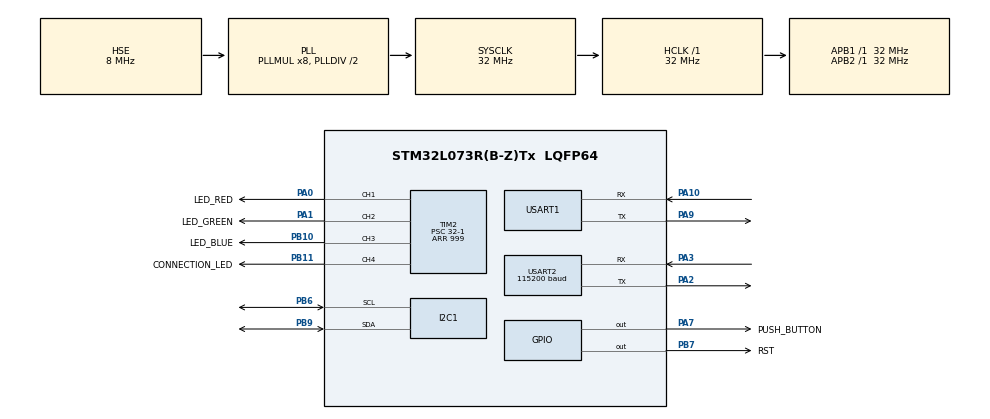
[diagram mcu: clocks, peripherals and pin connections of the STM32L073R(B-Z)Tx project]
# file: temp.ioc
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I2C1.Timing=0x00B07CB4
Mcu.Family=STM32L0
Mcu.Name=STM32L073R(B-Z)Tx
Mcu.Package=LQFP64
NVIC.USART1_IRQn=true\:0\:0\:false\:false\:true\:true\:true\:true
PA0.GPIO_Label=LED_RED
PA0.Signal=S_TIM2_CH1
PA1.GPIO_Label=LED_GREEN
PA1.Signal=S_TIM2_CH2
PA10.Mode=Asynchronous
PA10.Signal=USART1_RX
PA13.Mode=Serial_Wire
PA13.Signal=SYS_SWDIO
PA14.Mode=Serial_Wire
PA14.Signal=SYS_SWCLK
PA2.Mode=Asynchronous
PA2.Signal=USART2_TX
PA3.Mode=Asynchronous
PA3.Signal=USART2_RX
PA7.GPIO_Label=PUSH_BUTTON
PA7.Signal=GPIO_Output
PA9.Mode=Asynchronous
PA9.Signal=USART1_TX
PB10.GPIO_Label=LED_BLUE
PB10.Signal=S_TIM2_CH3
PB11.GPIO_Label=CONNECTION_LED
PB11.Signal=S_TIM2_CH4
PB6.Mode=I2C
PB6.Signal=I2C1_SCL
PB7.GPIO_Label=RST
PB7.Signal=GPIO_Output
PB9.Mode=I2C
PB9.Signal=I2C1_SDA
PH0-OSC_IN.Mode=HSE-External-Clock-Source
PH0-OSC_IN.Signal=RCC_OSC_IN
ProjectManager.HeapSize=0x200
ProjectManager.StackSize=0x400
ProjectManager.TargetToolchain=STM32CubeIDE
RCC.AHBFreq_Value=32000000
RCC.APB1Freq_Value=32000000
RCC.APB1TimFreq_Value=32000000
RCC.APB2Freq_Value=32000000
RCC.APB2TimFreq_Value=32000000
RCC.HCLKFreq_Value=32000000
RCC.HSE_VALUE=8000000
RCC.HSI16_VALUE=16000000
RCC.HSI48_VALUE=48000000
RCC.HSI_VALUE=16000000
RCC.LSE_VALUE=32768
RCC.MSI_VALUE=2097000
RCC.PLLMUL=RCC_PLLMUL_8
RCC.PLLSourceVirtual=RCC_PLLSOURCE_HSE
RCC.SYSCLKFreq_VALUE=32000000
RCC.SYSCLKSource=RCC_SYSCLKSOURCE_PLLCLK
RCC.VCOOutputFreq_Value=64000000
SH.S_TIM2_CH1.0=TIM2_CH1,PWM Generation1 CH1
SH.S_TIM2_CH2.0=TIM2_CH2,PWM Generation2 CH2
SH.S_TIM2_CH3.0=TIM2_CH3,PWM Generation3 CH3
SH.S_TIM2_CH4.0=TIM2_CH4,PWM Generation4 CH4
TIM2.Channel-PWM\ Generation1\ CH1=TIM_CHANNEL_1
TIM2.Channel-PWM\ Generation2\ CH2=TIM_CHANNEL_2
TIM2.Channel-PWM\ Generation3\ CH3=TIM_CHANNEL_3
TIM2.Channel-PWM\ Generation4\ CH4=TIM_CHANNEL_4
TIM2.Period=999
TIM2.Prescaler=32-1
TIM6.Period=65535-1
TIM6.Prescaler=32-1
USART1.VirtualMode-Asynchronous=VM_ASYNC
USART2.BaudRate=115200
USART2.VirtualMode-Asynchronous=VM_ASYNC
VP_TIM6_VS_ClockSourceINT.Mode=Enable_Timer
board=NUCLEO-L073RZ

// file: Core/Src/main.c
/* USER CODE BEGIN Header */
/**
 ******************************************************************************
 * @file           : main.c
 * @brief          : Main program body
 ******************************************************************************
 * @attention
 *
 * Copyright (c) 2026 STMicroelectronics.
 * All rights reserved.
 *
 * This software is licensed under terms that can be found in the LICENSE file
 * in the root directory of this software component.
 * If no LICENSE file comes with this software, it is provided AS-IS.
 *
 ******************************************************************************
 */
/* USER CODE END Header */
#include "main.h"
#include "i2c.h"
#include "tim.h"
#include "usart.h"
#include "gpio.h"

/* USER CODE BEGIN Includes */
#include "app/entry.h"
/* USER CODE END Includes */

void SystemClock_Config(void);

int main(void)
{

  /* MCU Configuration--------------------------------------------------------*/

  /* Reset of all peripherals, Initializes the Flash interface and the Systick. */
  HAL_Init();

  /* Configure the system clock */
  SystemClock_Config();

  /* Initialize all configured peripherals */
  MX_GPIO_Init();
  MX_I2C1_Init();
  MX_TIM2_Init();
  MX_TIM6_Init();
  MX_USART1_UART_Init();
  MX_USART2_UART_Init();
  /* USER CODE BEGIN 2 */

	app_main();

  /* USER CODE END 2 */

  /* Infinite loop */
	while (1)
	{

	}
}

void SystemClock_Config(void)
{
  RCC_OscInitTypeDef RCC_OscInitStruct = {0};
  RCC_ClkInitTypeDef RCC_ClkInitStruct = {0};
  RCC_PeriphCLKInitTypeDef PeriphClkInit = {0};

  /** Configure the main internal regulator output voltage
  */
  __HAL_PWR_VOLTAGESCALING_CONFIG(PWR_REGULATOR_VOLTAGE_SCALE1);

  /** Initializes the RCC Oscillators according to the specified parameters
  * in the RCC_OscInitTypeDef structure.
  */
  RCC_OscInitStruct.OscillatorType = RCC_OSCILLATORTYPE_HSE;
  RCC_OscInitStruct.HSEState = RCC_HSE_BYPASS;
  RCC_OscInitStruct.PLL.PLLState = RCC_PLL_ON;
  RCC_OscInitStruct.PLL.PLLSource = RCC_PLLSOURCE_HSE;
  RCC_OscInitStruct.PLL.PLLMUL = RCC_PLLMUL_8;
  RCC_OscInitStruct.PLL.PLLDIV = RCC_PLLDIV_2;
  if (HAL_RCC_OscConfig(&RCC_OscInitStruct) != HAL_OK)
  {
    Error_Handler();
  }

  /** Initializes the CPU, AHB and APB buses clocks
  */
  RCC_ClkInitStruct.ClockType = RCC_CLOCKTYPE_HCLK|RCC_CLOCKTYPE_SYSCLK
                              |RCC_CLOCKTYPE_PCLK1|RCC_CLOCKTYPE_PCLK2;
  RCC_ClkInitStruct.SYSCLKSource = RCC_SYSCLKSOURCE_PLLCLK;
  RCC_ClkInitStruct.AHBCLKDivider = RCC_SYSCLK_DIV1;
  RCC_ClkInitStruct.APB1CLKDivider = RCC_HCLK_DIV1;
  RCC_ClkInitStruct.APB2CLKDivider = RCC_HCLK_DIV1;

  if (HAL_RCC_ClockConfig(&RCC_ClkInitStruct, FLASH_LATENCY_1) != HAL_OK)
  {
    Error_Handler();
  }
  PeriphClkInit.PeriphClockSelection = RCC_PERIPHCLK_USART1|RCC_PERIPHCLK_USART2
                              |RCC_PERIPHCLK_I2C1;
  PeriphClkInit.Usart1ClockSelection = RCC_USART1CLKSOURCE_PCLK2;
  PeriphClkInit.Usart2ClockSelection = RCC_USART2CLKSOURCE_PCLK1;
  PeriphClkInit.I2c1ClockSelection = RCC_I2C1CLKSOURCE_PCLK1;
  if (HAL_RCCEx_PeriphCLKConfig(&PeriphClkInit) != HAL_OK)
  {
    Error_Handler();
  }
}

void Error_Handler(void)
{
	__disable_irq();
	while (1)
	{
	}
}
